# TC37XPD register map
Vendor: Infineon; Series: ATVMC; File version: 100
CPU: other r0p0, little endian, MPU, FPU, vendor SysTick, 4 interrupt priority bits
Registers are 32-bit, read-write, reset 0x0 unless marked. A register's access mark holds for its fields unless they carry their own. Offsets are from the block's base; [hi:lo] are bit positions; lines under a group give offsets from that group; {n}, {i} and the like mark numbered series; 'fields as' and 'values as' point back to an identical list.

## EVADC
Base 0xF0020000
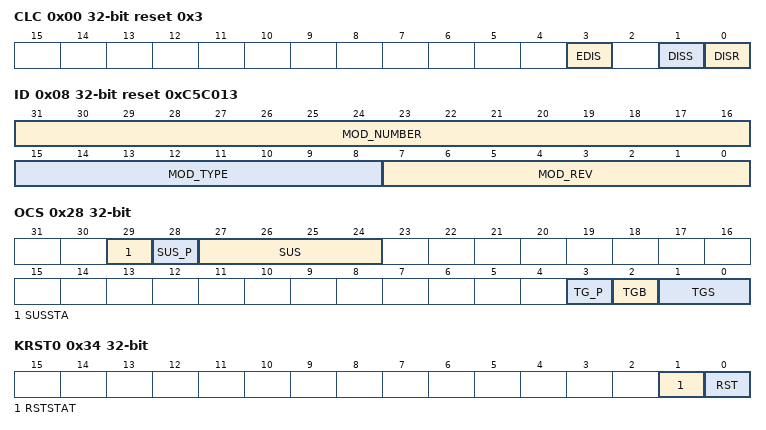
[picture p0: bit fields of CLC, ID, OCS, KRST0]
0x00 CLC access per field reset 0x3 — Clock Control Register resetvalue={Application Reset:0x3}
  [3] EDIS rw — Sleep Mode Enable Control EDIS. Used to control the module 8217 s reaction to sleep mode.
  [1] DISS ro — Module Disable Status Bit DISS
  [0] DISR rw — Module Disable Request Bit DISR. Used for enable disable control of the module. Also the analog section is disabled by clearing ANONS.
0x08 ID ro reset 0xC5C013 — Module Identification Register resetvalue={PowerOn Reset:0x0C5C013}
  [31:16] MOD_NUMBER — Module Number MOD NUMBER. Indicates the module identification number 00C5 SARADC .
  [15:8] MOD_TYPE — Module Type MOD TYPE. This internal marker is fixed to C0 .
  [7:0] MOD_REV — Module Revision MOD REV. Indicates the revision number of the implementation. This information depends on the design step.
0x28 OCS access per field — OCDS Control and Status Register resetvalue={PowerOn Reset:0x0,Debug Reset:0x0}
  [29] SUSSTA ro — Suspend State SUSSTA
  [28] SUS_P wo — SUS Write Protection SUS P. SUS is only written when SUS P is 1 otherwise unchanged. Read as 0.
  [27:24] SUS rw — OCDS Suspend Control SUS. Controls the sensitivity to the suspend signal coming from the OCDS Trigger Switch OTGS Not listed combinations are reserved. Same as 0000 .
  [3] TG_P wo — TGS TGB Write Protection TG P. TGS and TGB are only written when TG P is 1 otherwise unchanged. Read as 0.
  [2] TGB rw — OTGB0 1 Bus Select TGB
  [1:0] TGS rw — Trigger Set for OTGB0 1 TGS
0x2C KRSTCLR wo — Kernel Reset Status Clear Register resetvalue={Application Reset:0x0}
  [0] CLR — Kernel Reset Status Clear CLR. Read always as 0.
0x30 KRST1 — Kernel Reset Register 1 resetvalue={Application Reset:0x0}
  [0] RST — Kernel Reset RST. Request a kernel reset. The reset is executed if the reset bits of both kernel reset registers are set. RST is cleared after the kernel reset was executed.
0x34 KRST0 access per field — Kernel Reset Register 0 resetvalue={Application Reset:0x0}
  [1] RSTSTAT ro — Kernel Reset Status RSTSTAT. Indicates an executed kernel reset. RSTSTAT is set after the execution of a kernel reset in the same clock cycle in which the reset bits are cleared. Clear RSTSTAT by setting bit CLR in register KRSTCLR.
  [0] RST rw — Kernel Reset RST. Request a kernel reset. The reset is executed if the reset bits of both kernel reset registers are set. RST is cleared after the kernel reset was executed.
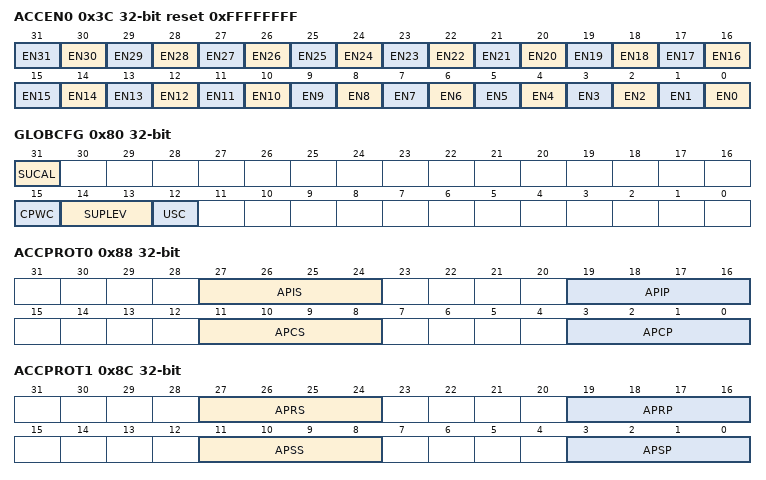
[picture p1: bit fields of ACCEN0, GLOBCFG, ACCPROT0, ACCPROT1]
0x3C ACCEN0 reset 0xFFFFFFFF — Access Enable Register 0 resetvalue={Application Reset:0x0FFFFFFFF}
  [n] EN{n} (n=0..31) — Access Enable for Master TAG ID 31 EN31. This bit enables write access to the module kernel addresses for transactions with the Master TAG ID x
0x80 GLOBCFG access per field — Global Configuration Register resetvalue={Application Reset:0x0}
  [31] SUCAL wo — Start Up Calibration SUCAL. Writing 1 to bit SUCAL initiates the start up calibration phase of all enabled analog converters except for the fast compare channels . Before and during start up calibration all converters must be inactive. After reset this is the case anyway.
  [15] CPWC wo — Write Control for Control Parameters CPWC
  [14:13] SUPLEV rw — Supply Voltage Level SUPLEV. Adjusts the analog circuitry to the supply voltage used in the application system. Make sure to keep SUPLEV 160 160 00 or 01 in the case of a 5 160 V supply.
  [12] USC rw — Unsynchronized Clock Generation USC. Defines the way the analog clock is generated.
0x88 ACCPROT0 — Access Protection Register 0 resetvalue={Application Reset:0x0}
  [27:24] APIS — Access Protection Initialization Secondary Groups. Each bit of this bitfield is associated with the corresponding group. 0 Full access to registers 1 Write access to initialization registers is blocked
  [19:16] APIP — Access Protection Initialization Primary Groups. Each bit of this bitfield is associated with the corresponding group. 0 Full access to registers 1 Write access to initialization registers is blocked
  [11:8] APCS — Access Protection Channel Control Secondary Groups. Each bit of this bitfield is associated with the corresponding group. 0 Full access to registers 1 Write access to channel control registers is blocked
  [3:0] APCP — Access Protection Channel Control Primary Groups. Each bit of this bitfield is associated with the corresponding group. 0 Full access to registers 1 Write access to channel control registers is blocked
0x8C ACCPROT1 — Access Protection Register 1 resetvalue={Application Reset:0x0}
  [27:24] APRS — Access Protection Result Registers Secondary Groups. Each bit of this bitfield is associated with the corresponding group. 0 Full access to registers 1 Write access to result registers is blocked
  [19:16] APRP — Access Protection Result Registers Primary Groups. Each bit of this bitfield is associated with the corresponding group. 0 Full access to registers 1 Write access to result registers is blocked
  [11:8] APSS — Access Protection Service Request Secondary Groups. Each bit of this bitfield is associated with the corresponding group. 0 Full access to registers 1 Write access to service request registers is blocked
  [3:0] APSP — Access Protection Service Request Primary Groups. Each bit of this bitfield is associated with the corresponding group. 0 Full access to registers 1 Write access to service request registers is blocked
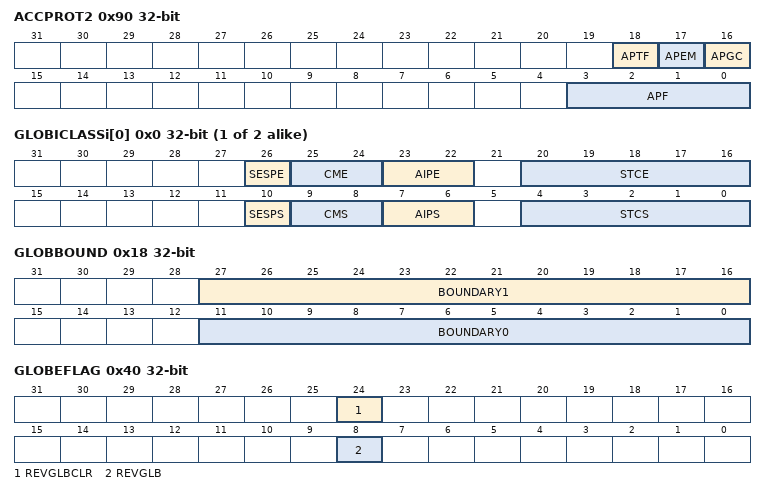
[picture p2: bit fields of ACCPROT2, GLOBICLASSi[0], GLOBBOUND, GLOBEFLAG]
0x90 ACCPROT2 — Access Protection Register 2 resetvalue={Application Reset:0x0}
  [18] APTF — Access Protection Test Function APTF
  [17] APEM — Access Protection External Multiplexer APEM
  [16] APGC — Access Protection Global Configuration APGC
  [3:0] APF — Access Protection Fast Compare Channels. Each bit of this bitfield is associated with the corresponding channel. 0 Full access to registers 1 Write access to fast compare channel registers is blocked
0xA0 GLOB group
  {0x0+4j} GLOBICLASSi[{j}] (j=0..1) — Input Class Register 0 Global resetvalue={Application Reset:0x0}
    [26] SESPE — Spread Early Sample Point for EMUX Conversions SESPE
    [25:24] CME — Conversion Mode for EMUX Conversions CME
    [23:22] AIPE — Analog Input Precharge Control for EMUX Conversions AIPE. Buffer must be enabled by BE 160 160 1 see GxANCFG .
    [20:16] STCE — Sample Time Control for EMUX Conversions STCE. Number of additional clock cycles to be added to the minimum sample phase of 2 sample clock cycles Coding and resulting sample time see CROSSREFERENCE . For conversions of standard channels the value from bitfield STCS is used.
    [10] SESPS — Spread Early Sample Point for Standard Conversions SESPS
    [9:8] CMS — Conversion Mode for Standard Conversions CMS
    [7:6] AIPS — Analog Input Precharge Control for Standard Conversions AIPS. Buffer must be enabled by BE 160 160 1 see GxANCFG .
    [4:0] STCS — Sample Time Control for Standard Conversions STCS. Number of additional clock cycles to be added to the minimum sample phase of 2 sample clock cycles Coding and resulting sample time see CROSSREFERENCE . For conversions of external channels the value from bitfield STCE can be used.
  0x18 GLOBBOUND — Global Boundary Select Register resetvalue={Application Reset:0x0}
    [27:16] BOUNDARY1 — Boundary Value 1 for Limit Checking BOUNDARY1. This value is compared against the conversion result.
    [11:0] BOUNDARY0 — Boundary Value 0 for Limit Checking BOUNDARY0. This value is compared against the conversion result.
  0x40 GLOBEFLAG access per field — Global Event Flag Register resetvalue={Application Reset:0x0}
    [24] REVGLBCLR wo — Clear Global Result Event REVGLBCLR
    [8] REVGLB rw — Global Result Event REVGLB
  0xA0 GLOBEVNP — Global Event Node Pointer Register resetvalue={Application Reset:0x0}
    [19:16] REV0NP — Service Request Node Pointer Global Result. Routes the corresponding event trigger to one of the service request lines nodes . For shared service request lines see common groups in the product specific appendix. Not listed combinations are reserved.
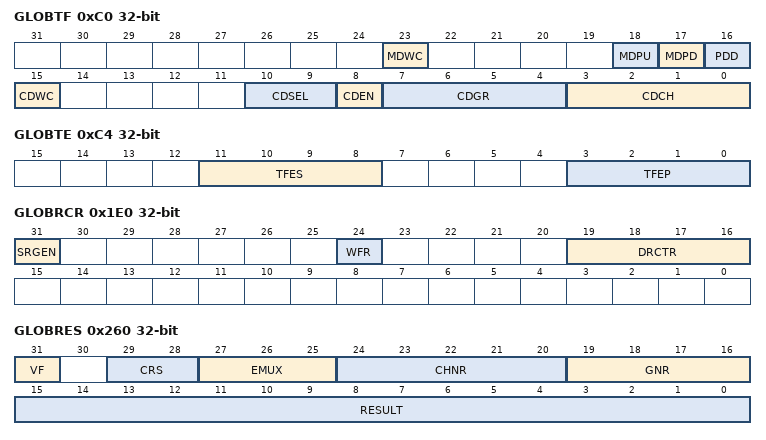
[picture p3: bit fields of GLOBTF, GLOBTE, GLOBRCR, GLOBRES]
  0xC0 GLOBTF access per field — Global Test Functions Register resetvalue={Application Reset:0x0}
    [23] MDWC wo — Write Control for Multiplexer Diagnostics MDWC
    [18] MDPU rw — Multiplexer Diagnostics Pull Up Devices Enable. Connecting combinations of pull up and or pull down devices generate various loads for testing. Channels with pull up diagnostics device are marked in the product specific appendix.
    [17] MDPD rw — Multiplexer Diagnostics Pull Down Devices Enable. Connecting combinations of pull up and or pull down devices generate various loads for testing. Channels with pull down diagnostics device are marked in the product specific appendix.
    [16] PDD rw — Pull Down Diagnostics Enable PDD. Channels with pull down diagnostics device are marked in the product specific appendix.
    [15] CDWC wo — Write Control for Conversion Diagnostics CDWC
    [10:9] CDSEL rw — Converter Diagnostics Pull Devices Select CDSEL
    [8] CDEN rw — Converter Diagnostics Enable CDEN
    [7:4] CDGR rw — Conversion Diagnostics Group CDGR. Defines the group number to be used for diagnostic conversions. Applies to all test functions of primary and secondary groups.
    [3:0] CDCH rw — Conversion Diagnostics Channel CDCH. Defines the channel number to be used for diagnostic conversions. Applies to MDPD MDPU.
  0xC4 GLOBTE — Global Test Enable Register resetvalue={Application Reset:0x0}
    [11:8] TFES — Test Function Enable Secondary Groups. Each bit of this bitfield is associated with the corresponding group. 0 No test functions for group x sequences 1 Test functions can be activated by group x sequences
    [3:0] TFEP — Test Function Enable Primary Groups. Each bit of this bitfield is associated with the corresponding group. 0 No test functions for group x sequences 1 Test functions can be activated by group x sequences
  0x1E0 GLOBRCR — Global Result Control Register resetvalue={Application Reset:0x0}
    [31] SRGEN — Service Request Generation Enable SRGEN
    [24] WFR — Wait for Read Mode Enable WFR. Refer also to Wait for Read Mode .
    [19:16] DRCTR — Data Reduction Control DRCTR. Defines how result values are stored accumulated in this register for the final result. The data reduction counter DRC can be loaded from this bitfield. Coding see CROSSREFERENCE Only standard data reduction is available for the global result register i.e. DMM is assumed as 00 .
  0x260 GLOBRES access per field — Global Result Register resetvalue={Application Reset:0x0}
    [31] VF rw — Valid Flag VF. Indicates a new result in bitfield RESULT.
    [29:28] CRS ro — Converted Request Source CRS. Indicates the request source that as requested the conversion to which the result value in bitfield RESULT belongs.
    [27:25] EMUX ro — External Multiplexer Setting EMUX. Indicates the setting of the external multiplexer corresponding to the value in bitfield RESULT.
    [24:20] CHNR ro — Channel Number CHNR. Indicates the channel number corresponding to the value in bitfield RESULT.
    [19:16] GNR ro — Group Number GNR. Indicates the group to which the channel number in bitfield CHNR refers.
    [15:0] RESULT rw — Result of most recent conversion RESULT. The position of the result bits within this bitfield depends on the configured operating mode. Refer to CROSSREFERENCE .
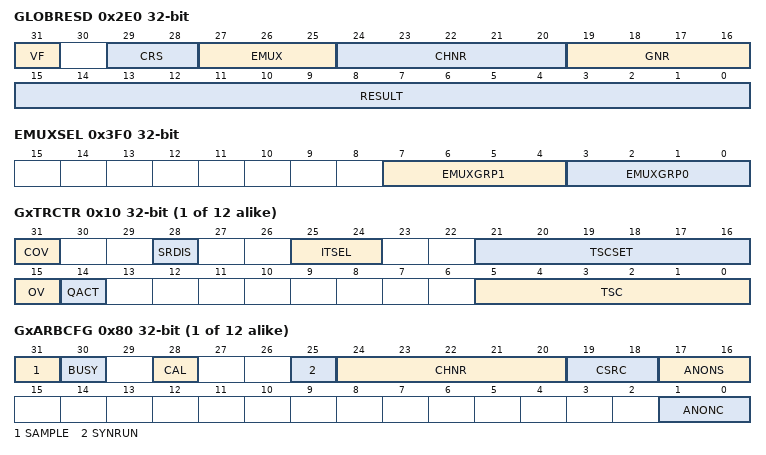
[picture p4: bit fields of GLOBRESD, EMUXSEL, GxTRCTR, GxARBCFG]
  0x2E0 GLOBRESD ro — Global Result Register Debug resetvalue={Application Reset:0x0}
    [31] VF — Valid Flag VF. Indicates a new result in bitfield RESULT.
    [29:28] CRS — Converted Request Source CRS. Indicates the request source that as requested the conversion to which the result value in bitfield RESULT belongs.
    [27:25] EMUX — External Multiplexer Setting EMUX. Indicates the setting of the external multiplexer corresponding to the value in bitfield RESULT.
    [24:20] CHNR — Channel Number CHNR. Indicates the channel number corresponding to the value in bitfield RESULT.
    [19:16] GNR — Group Number GNR. Indicates the group to which the channel number in bitfield CHNR refers.
    [15:0] RESULT — Result of most recent conversion RESULT. The position of the result bits within this bitfield depends on the configured operating mode. Refer to CROSSREFERENCE .
0x3F0 EMUXSEL — External Multiplexer Interface Select Register resetvalue={Application Reset:0x0}
  [7:4] EMUXGRP1 — External Multiplexer Group for Interface 1. Defines the group whose external multiplexer control signals are routed to EMUX interface 1 pins EMUX1x .
  [3:0] EMUXGRP0 — External Multiplexer Group for Interface 0. Defines the group whose external multiplexer control signals are routed to EMUX interface 0 pins EMUX0x .
{0x400+0x400*i} G[{i}] (i=0..11) group
  0x10 GxTRCTR access per field — Trigger Control Register Group 0 resetvalue={Application Reset:0x0}
    [31] COV wo — Clear Overflow Flag COV
    [28] SRDIS rw — Service Request Disable SRDIS. Controls if the source event of the selected trigger source also activates a service request.
    [25:24] ITSEL rw — Internal Trigger Input Selection ITSEL. Internal triggers are generated by the respective source events. Enable a source event in the selected request source to generate an internal trigger signal. The selected trigger signal is internally connected to gate input GxREQGTP of this request source. It is selected when XTSEL GTSEL 1111 .
    [21:16] TSCSET rw — Trigger Sequence Counter Start Value TSCSET. Defines the initial value of the trigger sequence counter TSC. TSC is reloaded with the value in TSCSET when a trigger occurs while TSC 00 . TSCSET is automatically copied to TSC when being written. CROSSREFERENCE
    [15] OV ro — Overflow Detected OV. Indicates that a trigger has been activated while the queue was still active QACT 160 160 1 . Cleared by writing 1 to bit COV.
    [14] QACT ro — Queue Active QACT. Indicates that request source Q2 is currently executing a sequence. Cleared by writing 1 to bit COV.
    [5:0] TSC ro — Trigger Sequence Counter TSC. Controls the effect of an incoming internal trigger If TSC gt 00 decrement TSC by one.
  0x80 GxARBCFG access per field — Arbitration Config. Register Group 0 resetvalue={Application Reset:0x0}
    [31] SAMPLE ro — Sample Phase Flag SAMPLE
    [30] BUSY ro — Converter Busy Flag BUSY
    [28] CAL ro — Start Up Calibration Active Indication CAL. Indicates the start up calibration phase of the corresponding analog converter. Start conversions only after the start up calibration phase is complete because a start up calibration will abort a running conversion.
    [25] SYNRUN ro — Synchronous Conversion Running SYNRUN. Indicates that a synchronized parallel conversion is currently running.
    [24:20] CHNR ro — Channel Number CHNR. Indicates the current or last converted analog input channel. This bitfield is updated when a conversion is started.
    [19:18] CSRC ro — Currently Converted Request Source CSRC. Indicates the arbitration slot number of the current BUSY 160 160 1 or of the last BUSY 160 160 0 conversion. This bitfield is updated when a conversion is started.
    [17:16] ANONS ro — Analog Converter Control Status ANONS. Defined by bitfield ANONC in a stand alone kernel or a kernel in master mode. In slave mode this bitfield is defined by bitfield ANONC of the respective master kernel. See also CROSSREFERENCE .
    [1:0] ANONC rw — Analog Converter Control ANONC. Defines the value of bitfield ANONS in a stand alone converter or a converter in master mode. Coding see ANONS or CROSSREFERENCE .
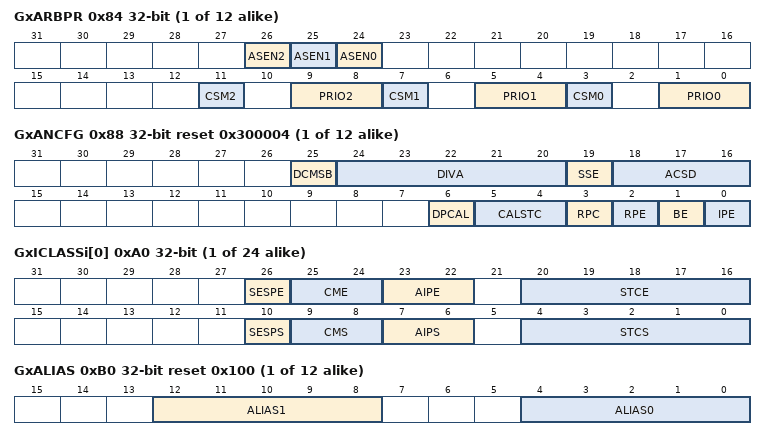
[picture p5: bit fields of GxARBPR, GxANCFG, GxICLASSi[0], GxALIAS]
  0x84 GxARBPR — Arbitration Priority Register Group 0 resetvalue={Application Reset:0x0}
    [26] ASEN2 — Arbitration Source Input 2 Enable. Enables the associated arbitration source input of the arbiter. The request source bits are not modified by write actions to ASENi.
    [25] ASEN1 — Arbitration Source Input 2 Enable. Enables the associated arbitration source input of the arbiter. The request source bits are not modified by write actions to ASENi.
    [24] ASEN0 — Arbitration Source Input 2 Enable. Enables the associated arbitration source input of the arbiter. The request source bits are not modified by write actions to ASENi.
    [11] CSM2 — Conversion Start Mode of Request Source 2
    [9:8] PRIO2 — Priority of Request Source i. Arbitration priority of request source i at input i
    [7] CSM1 — Conversion Start Mode of Request Source 2
    [5:4] PRIO1 — Priority of Request Source i. Arbitration priority of request source i at input i
    [3] CSM0 — Conversion Start Mode of Request Source 2
    [1:0] PRIO0 — Priority of Request Source i. Arbitration priority of request source i at input i
  0x88 GxANCFG reset 0x300004 — Analog Fct. Config. Register Group 0 resetvalue={Application Reset:0x300004}
    [25] DCMSB — Double Clock for the MSB Conversion DCMSB. Selects an additional clock cycle for the conversion step of the MSB.
    [24:20] DIVA — Divider Factor for the Analog Internal Clock DIVA. Defines the frequency of the analog converter clock f ADCI base clock for conversion steps derived from the peripheral clock f ADCI f ADC CP.
    [19] SSE — Sample Synchronization Enable SSE. See section CROSSREFERENCE .
    [18:16] ACSD — Analog Clock Synchronization Delay ACSD. Defines the delay of the analog clock in clocks after the sync signal. Do not exceed the current DIVA setting for the clock delay. Valid only if the phase synchronizer is selected USC 160 160 0
    [6] DPCAL — Disable Post Calibration DPCAL
    [5:4] CALSTC — Calibration Sample Time Control CALSTC
    [3] RPC — Reference Precharge Control RPC
    [2] RPE — Reference Precharge Enable RPE. Enabled after reset.
    [1] BE — Input Buffer Enable BE
    [0] IPE — Idle Precharge Enable IPE
  {0xA0+4j} GxICLASSi[{j}] (j=0..1) — Input Class Register 0 Group 0 resetvalue={Application Reset:0x0}
    fields as GLOB.GLOBICLASSi[0]
  0xB0 GxALIAS reset 0x100 — Alias Register Group 0 resetvalue={Application Reset:0x100}
    [12:8] ALIAS1 — Alias Value for CH1 Conversion Requests ALIAS1. Indicates the channel that is converted instead of channel CH1. The conversion is done with the settings defined for channel CH1.
    [4:0] ALIAS0 — Alias Value for CH0 Conversion Requests ALIAS0. Indicates the channel that is converted instead of channel CH0. The conversion is done with the settings defined for channel CH0.
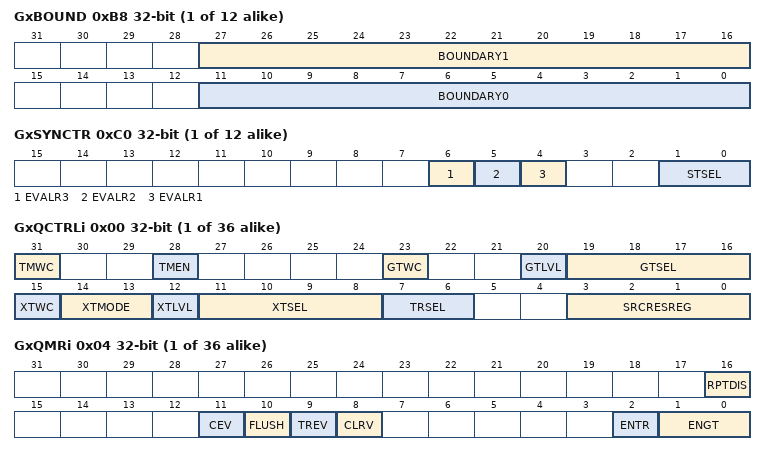
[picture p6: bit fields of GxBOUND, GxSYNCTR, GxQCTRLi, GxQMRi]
  0xB8 GxBOUND — Boundary Select Register Group 0 resetvalue={Application Reset:0x0}
    fields as GLOB.GLOBBOUND
  0xC0 GxSYNCTR — Synchronization Control Register Group 0 resetvalue={Application Reset:0x0}
    [6] EVALR3 — Evaluate Ready Input Ri. Enables the ready input signal for a kernel of a synchronization group.
    [5] EVALR2 — Evaluate Ready Input Ri. Enables the ready input signal for a kernel of a synchronization group.
    [4] EVALR1 — Evaluate Ready Input Ri. Enables the ready input signal for a kernel of a synchronization group.
    [1:0] STSEL — Start Selection STSEL. Controls the synchronization mechanism of the ADC kernel. Control inputs CIx see CROSSREFERENCE connected kernels see product specific appendix.
  {0x100+0x20*j} Q[{j}] (j=0..2) group
    0x00 GxQCTRLi access per field — Queue 0 Source Contr. Register Group 0 resetvalue={Application Reset:0x0}
      [31] TMWC wo — Write Control for Timer Mode TMWC
      [28] TMEN rw — Timer Mode Enable TMEN
      [23] GTWC wo — Write Control for Gate Configuration GTWC
      [20] GTLVL ro — Gate Input Level GTLVL. Current level of the selected gate input
      [19:16] GTSEL rw — Gate Input Selection GTSEL. The connected gate input signals are listed in the product specific appendix. GTSEL 160 160 1111 uses the selected internal trigger source for queue 2.
      [15] XTWC wo — Write Control for Trigger Configuration XTWC
      [14:13] XTMODE rw — Trigger Operating Mode XTMODE
      [12] XTLVL ro — External Trigger Level XTLVL. Current level of the selected trigger input
      [11:8] XTSEL rw — External Trigger Input Selection XTSEL. The connected trigger input signals are listed in the product specific appendix. XTSEL 160 160 1111 uses the selected gate input as trigger source ENGT must be 0X .
      [7:6] TRSEL rw — Trigger Source Selection TRSEL. Daisy chaining via source events from the corresponding adjacent request source Qi. Use XTMODE 10 B .
      [3:0] SRCRESREG rw — Source specific Result Register SRCRESREG
    0x04 GxQMRi access per field — Queue 0 Mode Register Group 0 resetvalue={Application Reset:0x0}
      [16] RPTDIS rw — Repeat Disable RPTDIS
      [11] CEV wo — Clear Event Flag CEV
      [10] FLUSH wo — Flush Queue FLUSH
      [9] TREV wo — Trigger Event TREV. Generates a software trigger for the request source. To trigger the request timer instead write 1 to bit GxREQTIMi.REQTS.
      [8] CLRV wo — Clear Valid Bit CLRV
      [2] ENTR rw — Enable External Trigger ENTR
      [1:0] ENGT rw — Enable Gate ENGT. Selects the gating functionality for the request source. REQGTx is the selected gating signal.
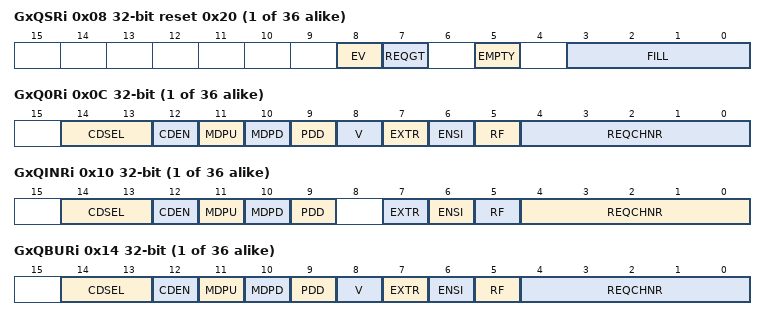
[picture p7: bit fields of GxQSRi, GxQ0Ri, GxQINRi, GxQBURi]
    0x08 GxQSRi ro reset 0x20 — Queue 0 Status Register Group 0 resetvalue={Application Reset:0x20}
      [8] EV — Event Detected EV. Indicates that an event has been detected while at least one valid entry has been in the queue queue register 0 or backup stage . Once set this bit is cleared automatically when the requested conversion is started.
      [7] REQGT — Request Gate Level REQGT. Monitors the level at the selected REQGT input.
      [5] EMPTY — Queue Empty EMPTY
      [3:0] FILL — Filling Level for Queue FILL. Indicates the number of valid queue entries. It is incremented each time a new entry is written to QINRx or by an enabled refill mechanism. It is decremented each time a requested conversion has been started. A new entry is ignored if the filling level has reached its maximum value. Maximum fill level for primary groups 8 entries Maximum fill level for secondary groups 16 entries
    0x0C GxQ0Ri ro — Queue 0 Register 0 Group 0 resetvalue={Application Reset:0x0}
      [14:13] CDSEL — Converter Diagnostics Pull Devices Select CDSEL
      [12] CDEN — Converter Diagnostics Enable CDEN
      [11] MDPU — Multiplexer Diagnostics Pull Devices Enable MDPD MDPU. Connecting combinations of pull up and or pull down devices generate various loads for testing. Channels with multiplexer diagnostics pull devices are marked in the product specific appendix.
      [10] MDPD — Multiplexer Diagnostics Pull Devices Enable MDPD MDPU. Connecting combinations of pull up and or pull down devices generate various loads for testing. Channels with multiplexer diagnostics pull devices are marked in the product specific appendix.
      [9] PDD — Pull Down Diagnostics Enable PDD. Channels with pull down diagnostics device are marked in the product specific appendix.
      [8] V — Request Channel Number Valid V. Indicates a valid queue entry in queue register 0.
      [7] EXTR — External Trigger EXTR. Enables external trigger events.
      [6] ENSI — Enable Source Interrupt ENSI
      [5] RF — Refill RF. Indicates the handling of handled requests.
      [4:0] REQCHNR — Request Channel Number REQCHNR. Indicates the channel number to be converted.
    0x10 GxQINRi wo — Queue 0 Input Register Group 0 resetvalue={Application Reset:0x0}
      [14:13] CDSEL — Converter Diagnostics Pull Devices Select CDSEL
      [12] CDEN — Converter Diagnostics Enable CDEN
      [11] MDPU — Multiplexer Diagnostics Pull Devices Enable MDPD MDPU. Connecting combinations of pull up and or pull down devices generate various loads for testing. Channels with multiplexer diagnostics pull devices are marked in the product specific appendix.
      [10] MDPD — Multiplexer Diagnostics Pull Devices Enable MDPD MDPU. Connecting combinations of pull up and or pull down devices generate various loads for testing. Channels with multiplexer diagnostics pull devices are marked in the product specific appendix.
      [9] PDD — Pull Down Diagnostics Enable PDD. Channels with pull down diagnostics device are marked in the product specific appendix.
      [7] EXTR — External Trigger EXTR. Enables the external trigger functionality. To use external triggers enable them by setting bit GxQMRy.ENTR.
      [6] ENSI — Enable Source Interrupt ENSI
      [5] RF — Refill RF
      [4:0] REQCHNR — Request Channel Number REQCHNR. Defines the channel number to be converted. Not available channel numbers are treated as channel 0.
    0x14 GxQBURi ro — Queue 0 Backup Register Group 0 resetvalue={Application Reset:0x0}
      [14:13] CDSEL — Converter Diagnostics Pull Devices Select CDSEL
      [12] CDEN — Converter Diagnostics Enable CDEN
      [11] MDPU — Multiplexer Diagnostics Pull Up Devices Enable. Connecting combinations of pull up and or pull down devices generate various loads for testing. Channels with multiplexer diagnostics pull devices are marked in the product specific appendix.
      [10] MDPD — Multiplexer Diagnostics Pull Down Devices Enable. Connecting combinations of pull up and or pull down devices generate various loads for testing. Channels with multiplexer diagnostics pull devices are marked in the product specific appendix.
      [9] PDD — Pull Down Diagnostics Enable PDD. Channels with pull down diagnostics device are marked in the product specific appendix.
      [8] V — Request Channel Number Valid V. Indicates if the entry REQCHNR RF TR ENSI in the queue backup register is valid. Bit V is set when a running conversion that has been requested by this request source is aborted it is cleared when the aborted conversion is restarted.
      [7] EXTR — External Trigger EXTR. The external trigger control bit of the aborted conversion
      [6] ENSI — Enable Source Interrupt ENSI. The enable source interrupt control bit of the aborted conversion
      [5] RF — Refill RF. The refill control bit of the aborted conversion
      [4:0] REQCHNR — Request Channel Number REQCHNR. The channel number of the aborted conversion that has been requested by this request source
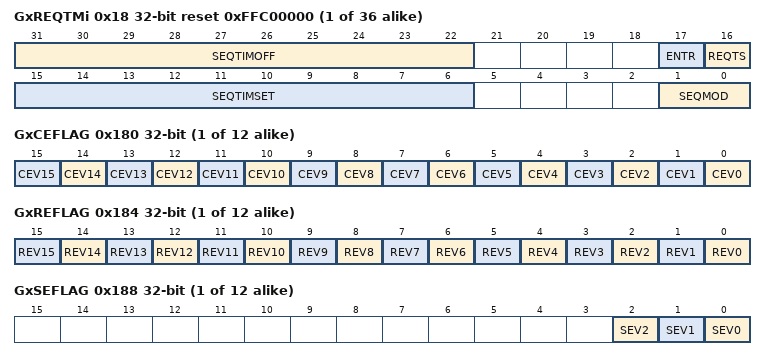
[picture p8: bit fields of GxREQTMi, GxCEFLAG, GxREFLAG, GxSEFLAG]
    0x18 GxREQTMi access per field reset 0xFFC00000 — Queue 0 Requ. Timer Mode Reg. Group 0 resetvalue={Application Reset:0x0FFC00000}
      [31:22] SEQTIMOFF rw — Sequence Timer Switch Off Value SEQTIMOFF. The generated trigger signal is disabled when the timer value is equal to or below this threshold.
      [17] ENTR rw — Enable External Trigger ENTR
      [16] REQTS wo — Request Timer Start Trigger REQTS
      [15:6] SEQTIMSET rw — Sequence Timer Set Value SEQTIMSET. Initial value for the sequence timer in steps of 16 215 t PER . This value is loaded into SEQTIMER when a new request timer period is started.
      [1:0] SEQMOD rw — Sequence Mode SEQMOD. Selects how the request timer controls the conversion sequence. Before changing the operating mode stop the sequence timer i.e. SEQMOD 00 .
    0x1C GxREQTSi ro — Queue 0 Requ. Timer Status Reg. Group 0 resetvalue={Application Reset:0x0}
      [15:6] SEQTIMER — Sequence Timer SEQTIMER. Counts the request timer periods in steps of 16 215 t ADC . This timer is loaded from bitfield SEQTIMSET at the beginning of a period.
  0x180 GxCEFLAG — Channel Event Flag Register Group 0 resetvalue={Application Reset:0x0}
    [n] CEV{n} (n=0..15) — Channel Event for Channel 15
  0x184 GxREFLAG — Result Event Flag Register Group 0 resetvalue={Application Reset:0x0}
    [n] REV{n} (n=0..15) — Result Event for Result Register 15
  0x188 GxSEFLAG — Source Event Flag Register Group 0 resetvalue={Application Reset:0x0}
    [2] SEV2 — Source Event i
    [1] SEV1 — Source Event i
    [0] SEV0 — Source Event i
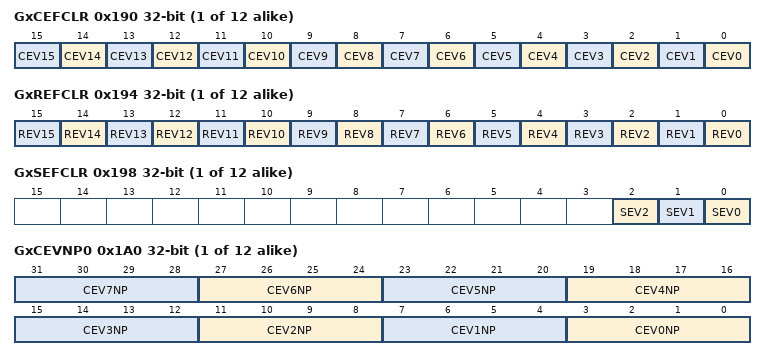
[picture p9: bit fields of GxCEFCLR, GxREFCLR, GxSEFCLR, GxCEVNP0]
  0x190 GxCEFCLR wo — Channel Event Flag Clear Register Group 0 resetvalue={Application Reset:0x0}
    [n] CEV{n} (n=0..15) — Clear Channel Event for Channel 15 CEV15
  0x194 GxREFCLR wo — Result Event Flag Clear Register Group 0 resetvalue={Application Reset:0x0}
    [n] REV{n} (n=0..15) — Clear Result Event for Result Register 15
  0x198 GxSEFCLR wo — Source Event Flag Clear Reg. Group 0 resetvalue={Application Reset:0x0}
    [2] SEV2 — Clear Source Event i
    [1] SEV1 — Clear Source Event i
    [0] SEV0 — Clear Source Event i
  0x1A0 GxCEVNP0 — Channel Event Node Pointer Reg. 0 Group 0 resetvalue={Application Reset:0x0}
    [4n+3:4n] CEV{n}NP (n=0..7) — Service Request Node Pointer Channel Event i. Routes the corresponding event trigger to one of the service request lines nodes . For shared service request lines see common groups in the product specific appendix. Not listed combinations are reserved.
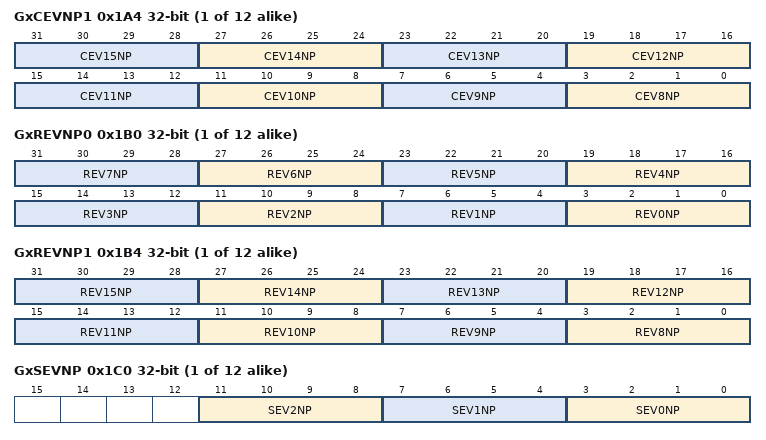
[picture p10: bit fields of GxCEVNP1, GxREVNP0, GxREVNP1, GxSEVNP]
  0x1A4 GxCEVNP1 — Channel Event Node Pointer Reg. 1 Group 0 resetvalue={Application Reset:0x0}
    [4n-29:4n-32] CEV{n}NP (n=8..15) — Service Request Node Pointer Channel Event i. Routes the corresponding event trigger to one of the service request lines nodes . For shared service request lines see common groups in the product specific appendix. Not listed combinations are reserved.
  0x1B0 GxREVNP0 — Result Event Node Pointer Reg. 0 Group 0 resetvalue={Application Reset:0x0}
    [4n+3:4n] REV{n}NP (n=0..7) — Service Request Node Pointer Result Event i. Routes the corresponding event trigger to one of the service request lines nodes . For shared service request lines see common groups in the product specific appendix. Not listed combinations are reserved.
  0x1B4 GxREVNP1 — Result Event Node Pointer Reg. 1 Group 0 resetvalue={Application Reset:0x0}
    [4n-29:4n-32] REV{n}NP (n=8..15) — Service Request Node Pointer Result Event i. Routes the corresponding event trigger to one of the service request lines nodes . For shared service request lines see common groups in the product specific appendix. Not listed combinations are reserved.
  0x1C0 GxSEVNP — Source Event Node Pointer Reg. Group 0 resetvalue={Application Reset:0x0}
    [all] fields
      15=Const_F15 (No service request line selected)
    [11:8] SEV2NP — Service Request Node Pointer Source Event i. Routes the corresponding event trigger to one of the service request lines nodes . For shared service request lines see common groups in the product specific appendix. Not listed combinations are reserved.
    [7:4] SEV1NP — Service Request Node Pointer Source Event i. Routes the corresponding event trigger to one of the service request lines nodes . For shared service request lines see common groups in the product specific appendix. Not listed combinations are reserved.
    [3:0] SEV0NP — Service Request Node Pointer Source Event i. Routes the corresponding event trigger to one of the service request lines nodes . For shared service request lines see common groups in the product specific appendix. Not listed combinations are reserved.
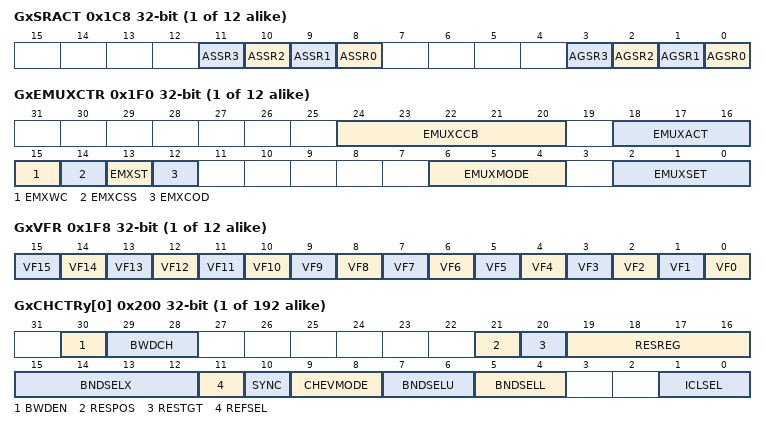
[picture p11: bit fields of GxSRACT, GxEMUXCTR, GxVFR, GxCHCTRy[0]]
  0x1C8 GxSRACT wo — Service Request Software Activation Trigger Group 0 resetvalue={Application Reset:0x0}
    [n+8] ASSR{n} (n=0..3) — Activate Shared Service Request Node 3 ASSR3
    [n] AGSR{n} (n=0..3) — Activate Group Service Request Node 3 AGSR3
  0x1F0 GxEMUXCTR access per field — External Multiplexer Control Reg. Group 0 resetvalue={Application Reset:0x0}
    [24:20] EMUXCCB rw — External Multiplexer Channel Selection for Block Mode EMUXCCB. Defines the channel that switches EMUXACT when converted. In block mode all EMUX channels use the same control value.
    [18:16] EMUXACT ro — External Multiplexer Actual Selection EMUXACT. Defines the current value for the external multiplexer selection. This bitfield is loaded from bitfield EMUXSET and modified according to the operating mode selected by bitfield EMUXMODE.
    [15] EMXWC wo — Write Control for EMUX Configuration EMXWC
    [14] EMXCSS rw — External Multiplexer Channel Selection Style EMXCSS
    [13] EMXST rw — External Multiplexer Sample Time Control EMXST
    [12] EMXCOD rw — External Multiplexer Coding Scheme EMXCOD
    [6:4] EMUXMODE rw — External Multiplexer Mode EMUXMODE. Not listed combinations are reserved. For single step mode sequence mode and block mode Select the start value with EMUXMODE 000 before selecting the respective mode.
    [2:0] EMUXSET rw — External Multiplexer Start Selection EMUXSET. Defines the initial selection for the external multiplexer.
  0x1F4 GxEMUXCS — Ext. Multiplexer Channel Select Reg. Group 0 resetvalue={Application Reset:0x0}
    [15:0] EMUXCH — External Multiplexer Channel Select EMUXCH. Defines the channel s to which the external multiplexer control is applied. EMXCSS 160 160 0 Channel number the lower 5 bits select an arbitrary channel valid numbers are limited by the number of available channels unused bits shall be 0 EMXCSS 160 160 1 Channel enable each bit enables the associated channel multiple channels can be selected enabled
  0x1F8 GxVFR — Valid Flag Register Group 0 resetvalue={Application Reset:0x0}
    [n] VF{n} (n=0..15) — Valid Flag of Result Register x VF15. Indicates a new result in bitfield RESULT.
  {0x200+4j} GxCHCTRy[{j}] (j=0..15) — Group 0 Channel 0 Control Register resetvalue={Application Reset:0x0}
    [30] BWDEN — Broken Wire Detection Enable BWDEN
    [29:28] BWDCH — Broken Wire Detection Channel BWDCH. Reserved combinations shall select VAGND.
    [21] RESPOS — Result Position RESPOS
    [20] RESTGT — Result Target RESTGT
    [19:16] RESREG — Result Register RESREG
    [15:12] BNDSELX — BoundaryExtension BNDSELX. While BNDSELX 8800 0000 bitfields BNDSELU and BNDSELL are concatenated and select the corresponding result register as lower boundary.
    [11] REFSEL — Reference Input Selection REFSEL. Defines the reference voltage input to be used for conversions on this channel. Some channels cannot select an alternate reference.
    [10] SYNC — Synchronization Request SYNC
    [9:8] CHEVMODE — Channel Event Mode CHEVMODE. Generate a channel event with limit checking The boundary band is defined as the area where the result is less than or equal to the selected upper boundary and greater than or equal to the selected lower boundary see CROSSREFERENCE .
    [7:6] BNDSELU — Upper Boundary Select BNDSELU
    [5:4] BNDSELL — Lower Boundary Select BNDSELL
    [1:0] ICLSEL — Input Class Select ICLSEL
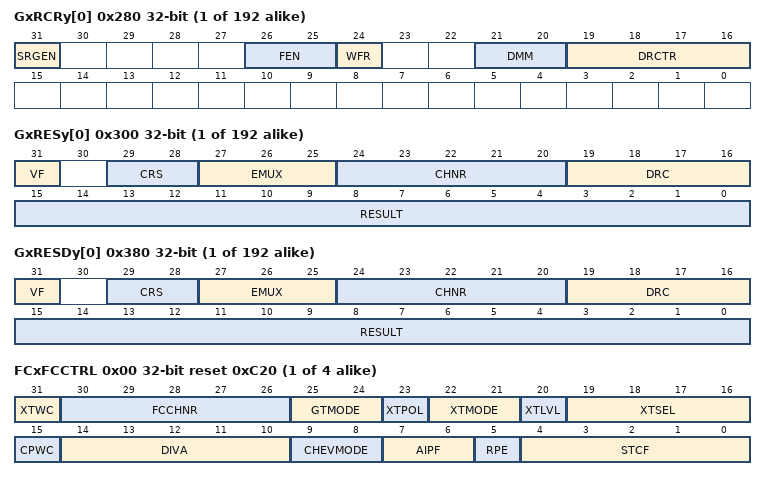
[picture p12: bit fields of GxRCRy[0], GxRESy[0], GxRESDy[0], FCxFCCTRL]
  {0x280+4j} GxRCRy[{j}] (j=0..15) — Group 0 Result Control Register 0 resetvalue={Application Reset:0x0}
    [31] SRGEN — Service Request Generation Enable SRGEN
    [26:25] FEN — FIFO Mode Enable FEN
    [24] WFR — Wait for Read Mode Enable WFR
    [21:20] DMM — Data Modification Mode DMM. See CROSSREFERENCE
    [19:16] DRCTR — Data Reduction Control DRCTR. Defines how result values are stored accumulated in this register for the final result. The data reduction counter DRC can be loaded from this bitfield. The function of bitfield DRCTR is determined by bitfield DMM.
  {0x300+4j} GxRESy[{j}] (j=0..15) access per field — Group 0 Result Register 0 resetvalue={Application Reset:0x0}
    [31] VF ro — Valid Flag VF. Indicates a new result in bitfield RESULT. Bit VF is automatically cleared upon reading register GxRESy.
    [29:28] CRS ro — Converted Request Source CRS. Indicates the request source that as requested the conversion to which the result value in bitfield RESULT belongs.
    [27:25] EMUX ro — External Multiplexer Setting EMUX. Indicates the setting of the external multiplexer corresponding to the value in bitfield RESULT. Available in GxRES0 only. Use GxRES0 if EMUX information is required.
    [24:20] CHNR ro — Channel Number CHNR. Indicates the channel number corresponding to the value in bitfield RESULT.
    [19:16] DRC ro — Data Reduction Counter DRC. Indicates the number of values still to be accumulated for the final result. The final result is available and valid flag VF is set when bitfield DRC becomes zero by decrementing or by reload . See CROSSREFERENCE
    [15:0] RESULT rw — Result of Most Recent Conversion RESULT. The position of the result bits within this bitfield depends on the configured operating mode. Refer to CROSSREFERENCE . Bitfield RESULT is writeable by the application to set the initial value for min max detection.
  {0x380+4j} GxRESDy[{j}] (j=0..15) ro — Group 0 Result Reg. 0 Debug resetvalue={Application Reset:0x0}
    [31] VF — Valid Flag VF. Indicates a new result in bitfield RESULT.
    [29:28] CRS — Converted Request Source CRS. Indicates the request source that as requested the conversion to which the result value in bitfield RESULT belongs.
    [27:25] EMUX — External Multiplexer Setting EMUX. Indicates the setting of the external multiplexer corresponding to the value in bitfield RESULT. Available in GxRESD0 only. Use GxRESD0 if EMUX information is required.
    [24:20] CHNR — Channel Number CHNR. Indicates the channel number corresponding to the value in bitfield RESULT.
    [19:16] DRC — Data Reduction Counter DRC. Indicates the number of values still to be accumulated for the final result. The final result is available and valid flag VF is set when bitfield DRC becomes zero by decrementing or by reload . See CROSSREFERENCE
    [15:0] RESULT — Result of Most Recent Conversion RESULT. The position of the result bits within this bitfield depends on the configured operating mode. Refer to CROSSREFERENCE .
{0x3400+0x100*i} FC[{i}] (i=0..3) group
  0x00 FCxFCCTRL access per field reset 0xC20 — Fast Compare Control Register FC Channel 0 resetvalue={Application Reset:0x0C20}
    [31] XTWC wo — Write Control for Trigger Gate Configuration XTWC
    [30:26] FCCHNR rw — Fast Compare Channel Cannel Number FCCHNR. Selects the input signal to be compared 1C 8230 1F select internal signals used for testing all other channel numbers are reserved. See 8220 Common Input Signals 8221 in the product specific appendix.
    [25:24] GTMODE rw — Gate Operating Mode GTMODE
    [23] XTPOL rw — External Trigger Polarity XTPOL
    [22:21] XTMODE rw — Trigger Operating Mode XTMODE
    [20] XTLVL ro — External Trigger Level XTLVL. Current level of the selected trigger input
    [19:16] XTSEL rw — External Trigger Input Selection XTSEL. The connected trigger input signals are listed in the product specific appendix. The selected input signal can be used as a trigger source or as a gate signal depending on the operating mode.
    [15] CPWC wo — Write Control for Control Parameters CPWC
    [14:10] DIVA rw — Divider Factor for the Analog Internal Clock DIVA. Defines the frequency of the analog converter clock f ADCI base clock for conversion steps derived from the peripheral clock f ADCI f ADC CP.
    [9:8] CHEVMODE rw — Channel Event Mode CHEVMODE. Generate a channel event For a service request summary refer to CROSSREFERENCE .
    [7:6] AIPF rw — Analog Input Precharge Enable for Fast Comparisons AIPF. The buffer is enabled automatically while AIPF 8800 00 .
    [5] RPE rw — Reference Precharge Enable RPE. Enabled after reset.
    [4:0] STCF rw — Sample Time Control for Fast Comparisons STCF. Number of additional clock cycles to be added to the minimum sample phase of 2 analog clock cycles Coding and resulting sample time see CROSSREFERENCE .
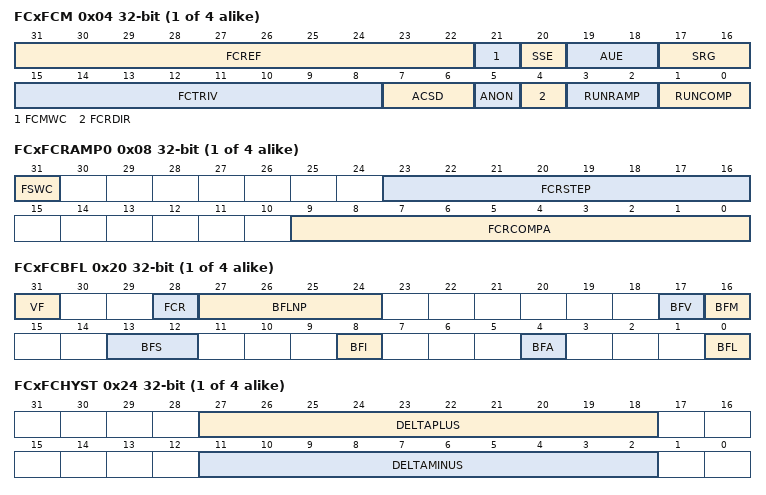
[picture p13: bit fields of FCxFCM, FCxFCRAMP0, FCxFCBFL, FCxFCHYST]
  0x04 FCxFCM access per field — Fast Compare Mode Register FC Channel 0 resetvalue={Application Reset:0x0}
    [31:22] FCREF rw — Fast Compare Reference Value FCREF. The input level is compared to this value. The resulting reference level is V AREF 1 xa0 024 xd7 lt FCREF gt .
    [21] FCMWC wo — Write Control for Fast Compare Mode Configuration FCMWC
    [20] SSE rw — Sample Synchronization Enable SSE. See section CROSSREFERENCE .
    [19:18] AUE rw — Automatic Update Enable AUE. Defines the source of the value s in bitfield FCREF.
    [17:16] SRG rw — Service Request Generation SRG. For a service request summary refer to CROSSREFERENCE .
    [15:8] FCTRIV rw — Fast Compare Trigger Interval FCTRIV. Defines the interval at which fast compare operations are triggered in steps of 16 215 1 f ADC .
    [7:6] ACSD rw — Analog Clock Synchronization Delay ACSD. Defines the delay of the analog clock in clocks after the sync signal. Do not exceed the current DIVA setting for the clock delay. Valid only if the phase synchronizer is selected USC 160 160 0
    [5] ANON rw — Analog Converter Control ANON. The extended wakeup time is required before the analog part is fully operable see CROSSREFERENCE .
    [4] FCRDIR rw — Fast Compare Ramp Direction FCRDIR
    [3:2] RUNRAMP rw — Run Control for Ramp RUNRAMP. Defines the run conditions for the ramp generation. Before changing the operating mode stop the ramp timer i.e. RUNRAMP 00 . REQTRx is the selected trigger signal.
    [1:0] RUNCOMP rw — Run Control for Compare Channel RUNCOMP. Defines the basic run conditions of the fast compare channel.
  0x08 FCxFCRAMP0 access per field — Fast Compare Ramp Register 0 FC Channel 0 resetvalue={Application Reset:0x0}
    [31] FSWC wo — Write Control for Fast Compare Stepwidth FSWC
    [23:16] FCRSTEP rw — Fast Compare Ramp Step Width FCRSTEP. Configures the prescaler for FCRCOUNT in increments of 8 215 1 f ADC .
    [9:0] FCRCOMPA rw — Fast Compare Ramp Compare Value A FCRCOMPA. The content of FCRCOMPA is copied to the ramp counter when a ramp is started i.e. upon the selected trigger event. The ramp counter defines the reference value during ramp generation. It is therefore copied to bitfield FCREF when the ramp is started and each time the counter changes. FCRCOMPA is also used in alternate value mode while the gate is active high .
  0x0C FCxFCRAMP1 — Fast Compare Ramp Register 1 FC Channel 0 resetvalue={Application Reset:0x0}
    [9:0] FCRCOMPB — Fast Compare Ramp Compare Value B FCRCOMPB. Defines the stop level of the generated ramp. FCRCOMPB is also used in alternate value mode while the gate is inactive low .
  0x20 FCxFCBFL access per field — Boundary Flag Register FC Channel 0 resetvalue={Application Reset:0x0}
    [31] VF ro — Valid Flag VF. Indicates a new result in bit FCR. Bit VF is automatically cleared upon reading register FCxFCBFL.
    [28] FCR ro — Fast Compare Result FCR. Indicates the last generated compare result If the input signal equals the reference value the analog comparator will return either quot above quot or quot below quot .
    [27:24] BFLNP rw — Boundary Flag Node Pointer. For shared service request lines see common groups in the product specific appendix. Not listed combinations are reserved. Shall be implemented as 1111 no common output.
    [17] BFV rw — Boundary Flag Value BFV. Defines the logic value that replaces the compare result while the gate input is inactive low in lock mode see also bitfield GTMODE in register GxFCCTRL
    [16] BFM rw — Boundary Flag Mode Control BFM
    [13:12] BFS wo — Boundary Flag Software Control BFS
    [8] BFI rw — Boundary Flag Inversion Control BFI
    [4] BFA rw — Boundary Flag Activation Select BFA
    [0] BFL ro — Boundary Flag BFL
  0x24 FCxFCHYST — Fast Comp. Hysteresis Register FC Channel 0 resetvalue={Application Reset:0x0}
    [27:18] DELTAPLUS — Upper Delta Value DELTAPLUS. This value is added to the reference value while the last result is 0
    [11:2] DELTAMINUS — Lower Delta Value DELTAMINUS. This value is subtracted from the reference value while the last result is 1
